# psoc6a2m register map
Vendor: Cypress Semiconductor; Series: psoc6a2m; File version: 1.0
CPU: CM4 r0p1, little endian, MPU, FPU, VTOR, 3 interrupt priority bits
Registers are 32-bit, read-write, reset 0x0 unless marked. A register's access mark holds for its fields unless they carry their own. Offsets are from the block's base; [hi:lo] are bit positions; lines under a group give offsets from that group; {n}, {i} and the like mark numbered series; 'fields as' and 'values as' point back to an identical list; <NAME> marks a mode.

## FLASHC — Flash controller
Base 0x40240000
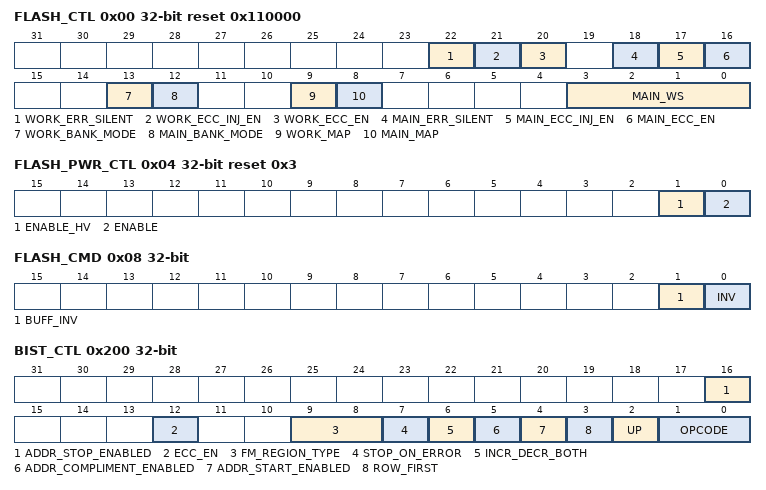
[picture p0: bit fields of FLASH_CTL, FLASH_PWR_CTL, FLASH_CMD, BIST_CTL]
0x00 FLASH_CTL reset 0x110000 — Control
  [22] WORK_ERR_SILENT — Specifies bus transfer behavior for a non-recoverable error on the FLASH macro work interface (either a non-correctable ECC error, a FLASH macro work interface internal error, a FLASH macro work interface memory hole access): '0': Bus transfer has a bus error. '1': Bus transfer does NOT have a bus error; i.e. the error is 'silent' In either case, the erroneous FLASH macro data is returned by the bus master interface. The erroneous data is NOT placed in a bus master interface's cache and/or buffer. This field is ONLY used by CPU bus transfers. Non-CPU bus transfers always have a bus transfer with a bus error, in case of a non-recoverable error. Note: All CPU bus masters have dedicated status registers (CM0_STATUS and CM4_STATUS) to register the occurence of FLASH macro work interface internal errors (non-correctable ECC errors and memory hole errors are NOT registered). Note: fault reporting can be used to identify the error that occured: - FLASH macro work interface internal error. - FLASH macro work interface non-recoverable ECC error. - FLASH macro work interface recoverable ECC error. - FLASH macro work interface memory hole error.
  [21] WORK_ECC_INJ_EN — Enable error injection for FLASH work interface. When '1', the parity (ECC_CTL.PARITY[6:0]) is used for a load from the ECC_CTL.WORD_ADDR[23:0] word address.
  [20] WORK_ECC_EN — Enable ECC checking for FLASH work interface: '0': Disabled. ECC checking/reporting on FLASH work interface is disabled. No correctable or non-correctable faults are reported. '1': Enabled.
  [18] MAIN_ERR_SILENT — Specifies bus transfer behavior for a non-recoverable error on the FLASH macro main interface (either a non-correctable ECC error, a FLASH macro main interface internal error, a FLASH macro main interface memory hole access): '0': Bus transfer has a bus error. '1': Bus transfer does NOT have a bus error; i.e. the error is 'silent' In either case, the erroneous FLASH macro data is returned by the bus master interface. The erroneous data is NOT placed in a bus master interface's cache and/or buffer. This field is ONLY used by CPU bus transfers. Non-CPU bus transfers always have a bus transfer with a bus error, in case of a non-recoverable error. Note: All CPU bus masters have dedicated status registers (CM0_STATUS and CM4_STATUS) to register the occurence of FLASH macro main interface internal errors (non-correctable ECC errors and memory hole errors are NOT registered). Note: fault reporting can be used to identify the error that occured: - FLASH macro main interface internal error. - FLASH macro main interface non-recoverable ECC error. - FLASH macro main interface recoverable ECC error. - FLASH macro main interface memory hole error.
  [17] MAIN_ECC_INJ_EN — Enable error injection for FLASH main interface. When '1', the parity (ECC_CTL.PARITY[7:0]) is used for a load from the ECC_CTL.WORD_ADDR[23:0] word address.
  [16] MAIN_ECC_EN — Enable ECC checking for FLASH main interface: '0': Disabled. ECC checking/reporting on FLASH main interface is disabled. No correctable or non-correctable faults are reported. '1': Enabled.
  [13] WORK_BANK_MODE — Specifies bank mode of FLASH macro work array. '0': Single bank mode. '1': Dual bank mode.
  [12] MAIN_BANK_MODE — Specifies bank mode of FLASH macro main array. '0': Single bank mode. '1': Dual bank mode.
  [9] WORK_MAP — Specifies mapping of FLASH macro work array. '0': Mapping A. '1': Mapping B. This field is only used when WORK_BANK_MODE is '1' (dual bank mode).
  [8] MAIN_MAP — Specifies mapping of FLASH macro main array. '0': Mapping A. '1': Mapping B. This field is only used when MAIN_BANK_MODE is '1' (dual bank mode).
  [3:0] MAIN_WS — FLASH macro main interface wait states: '0': 0 wait states. ... '15': 15 wait states
0x04 FLASH_PWR_CTL reset 0x3 — Flash power control
  [1] ENABLE_HV — Controls 'enable_hv' pin of the Flash memory.
  [0] ENABLE — Controls 'enable' pin of the Flash memory.
0x08 FLASH_CMD — Command
  [1] BUFF_INV — Invalidation of ALL buffers (does not invalidate the caches). SW writes a '1' to clear the buffers. HW sets this field to '0' when the operation is completed. The operation takes a maximum of three clock cycles on the slowest of the clk_slow and clk_fast clocks. Note: the caches only capture FLASH macro main array data. Therefore, invalidating just the buffers (BUFF_INV) does not invalidate captures main array data in the caches.
  [0] INV — Invalidation of ALL caches (for CM0+ and CM4) and ALL buffers. SW writes a '1' to clear the caches. HW sets this field to '0' when the operation is completed. The operation takes a maximum of three clock cycles on the slowest of the clk_slow and clk_fast clocks. The caches' LRU structures are also reset to their default state.
0x200 BIST_CTL — BIST control
  [16] ADDR_STOP_ENABLED — Specifies Flash BIST stop addresses: '0': Row and column addresses stop with their maximum/minimum values. '1': Row and column addresses stop with their values as specified by BIST_ADDR_STOP. This feature is supported only for simple increment/decrement patterns. It is not supported with address compliment pattern (BIST_CTL.ADDR_COMPLIMENT_ENABLED) or address pattern which increments/decrements both row address and column address (BIST_CTL.INCR_DECR_BOTH) for every read.
  [12] ECC_EN — Enable to test ECC data from Flash 0: ECC data output from Flash is not included for BIST test 1: ECC data output from Flash is included for BIST test
  [9:8] FM_REGION_TYPE — Specifies the Flash macro region to be tested. For eCT Flash 2'b00: Small sector region (SMS). 2'b01: Large sector region. 2'b1x: OTP region. This option is valid only when running BIST for eCT MAIN interface. Ignored when running BIST on WORK interface. For SONOS Flash 2'b00: Main flash region 2'b01: EEPROM region 2'b1x: SFLASH region
  [7] STOP_ON_ERROR — Specifies the BIST to continue indefinitely, regardless of occurrence of errors or not. '0': BIST controller doesn't stop on the data failures, it continues regardless of the errors. '1': BIST controller stops on when the first data failure is encounted.
  [6] INCR_DECR_BOTH — Specifies to generate patterns where both column address and row address are incremented/decremented simultaneously. '0': Generate normal increment/decrement patterns. '1': Generate address patterns with both row and column address changing. Example: With UP = 1 and ROW_FIRST = 0 00_00 01_01 10_10 11_11 00_01 01_10 10_11 11_00 00_10 ...
  [5] ADDR_COMPLIMENT_ENABLED — Specifies to generate address compliment patterns. '0': Generate normal increment/decrement patterns. '1': Generate address patterns which interleaves compliment of previous address in between. Example: The following is an exaple pattern, With UP=1 and ROW_FIRST =0 00_00 11_11 00_01 11_10 00_10 11_01 ...
  [4] ADDR_START_ENABLED — Specifies Flash BIST start addresses: '0': Row and column addresses start with their maximum/minimum values. '1': Row and column addresses start with their values as specified by BIST_ADDR_START. This feature is supported only for simple increment/decrement patterns. It is not supported with address compliment pattern (BIST_CTL.ADDR_COMPLIMENT_ENABLED) or address pattern which increments/decrements both row address and column address (BIST_CTL.INCR_DECR_BOTH) for every read.
  [3] ROW_FIRST — Specifies how the Flash BIST addresses are generated: '0': Column address is incremented/decremented till it reaches its maximum/minimum value. Once it reach its maximum/minimum value, it is set to its mimimum/maximum value and only then is the row address incremented/decremented. '1': Row address is incremented/decremented till it reaches its maximum/minimum value. Once it reach its maximum/minimum value, it is set to its mimimum/maximum value and only then is the column address incremented/decremented.
  [2] UP — Specifies direction in which Flash BIST steps through addresses: ''0': BIST steps through the Flash from the maximum row and column addresses (as specified by a design time configurtion parameter when ADDR_START_ENABLED is '0' and as specified by BIST_ADDR_START when ADDR_START_ENABLED is '1') to the minimum row and column addresses. '1': BIST steps through the Flash from the minimum row and column addresses ('0' when ADDR_START_ENABLED is '0' and as specified by BIST_ADDR_START when ADDR_START_ENABLED is '1') to the maximum row and column addresses.
  [1:0] OPCODE — This field specifies how the data check should be performed after reading the data from Flash memory. '0': Read the Flash and compare the output to BIST_DATA (R0). '1': Read the Flash and compare the output to the binary complement of BIST_DATA (R1). '2': Read the Flash and compare with BIST_DATA[] and compliment of BIST_DATA alternately (R01). The expected data of the first read is BIST_DATA, expected data of the second read is binary compliment of BIST_DATA, third read expected data is BIST_DATA, fourth read expected data is binary compliment of BIST_DATA and so on. '3': Similar to '2', but enables checker board pattern (where as OPCODE = 2 gives column stripe pattern). Note: OPCODE = 2 or 3 doesn;t support INCR_DECR_BOTH = 1 and ADDR_COMPLIMENT_ENABLED = 1.
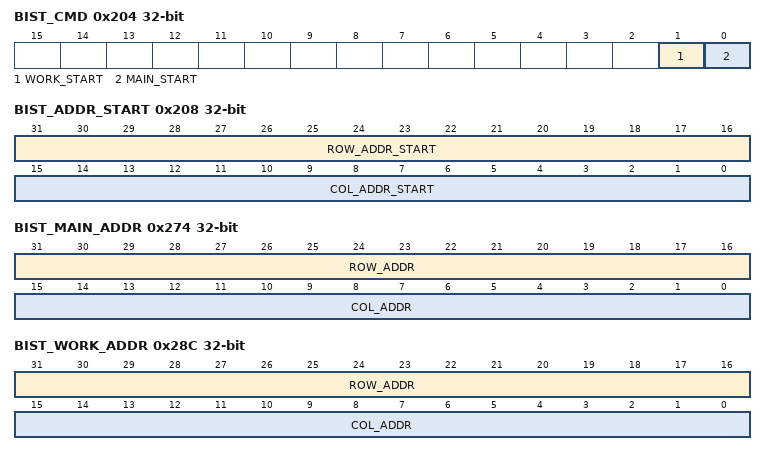
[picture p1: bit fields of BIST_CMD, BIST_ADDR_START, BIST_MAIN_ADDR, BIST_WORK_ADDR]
0x204 BIST_CMD — BIST command
  [1] WORK_START — 1': Start FLASH WORK BIST. Hardware set this field to '0' when BIST is completed.
  [0] MAIN_START — 1': Start FLASH MAIN BIST. Hardware set this field to '0' when BIST is completed.
0x208 BIST_ADDR_START — BIST address start register
  [31:16] ROW_ADDR_START — Row start address. Useful to apply BIST to a part of an Flash. The value of this field should be in a legal range (a value outside of the legal range has an undefined result, and may lock up the BIST state machine). This legal range is dependent on the number of rows of the SRAM the BIST is applied to (as specified by BIST_CTL.SRAMS_ENABLED). E.g. for a Flash with m columns, the legal range is [0, m-1].
  [15:0] COL_ADDR_START — Column start address. Useful to apply BIST to a part of an Flash. The value of this field should be in a legal range (a value outside of the legal range has an undefined result, and may lock up the BIST state machine). This legal range is dependent on the number of columns of the SRAM the BIST is applied to (as specified by BIST_CTL.SRAMS_ENABLED). E.g. for a Flash with n columns, the legal range is [0, n-1].
{0x20C+4i} BIST_DATA[{i}] (i=0..7) — BIST data register(s)
  [31:0] DATA — BIST data register to store the expected value for data comparison. For a 128-bit Flash memory, there will be 4 BIST_DATA registers to store 128-bit value.
{0x22C+4i} BIST_MAIN_DATA_ACT[{i}] (i=0..7) ro reset not defined — BIST (main) data actual register(s)
  [31:0] DATA — This field specified the actual Flash data output that caused the BIST failure.
{0x24C+4i} BIST_MAIN_DATA_EXP[{i}] (i=0..7) ro reset not defined — BIST (main) data expected register(s)
  [31:0] DATA — This field specified the expected Flash data output.
0x26C BIST_MAIN_DATA_ECC_ACT ro reset not defined — BIST (main) ECC data actual register
  [31:0] DATA — This field specified the actual Flash ECC data output.
0x270 BIST_MAIN_DATA_ECC_EXP ro reset not defined — BIST (main) ECC data expected register
  [31:0] DATA — This field specified the expected Flash ECC data output.
0x274 BIST_MAIN_ADDR ro reset not defined — BIST (main) address register
  [31:16] ROW_ADDR — Current row address.
  [15:0] COL_ADDR — Current column address.
0x278 BIST_MAIN_STATUS
  [0] FAIL — 0': BIST passed. '1': BIST failed.
0x27C BIST_WORK_DATA_ACT ro reset not defined — BIST (work) data actual register
  [31:0] DATA — This field specified the actual work Flash data output that caused the BIST failure.
0x280 BIST_WORK_DATA_EXP ro reset not defined — BIST (work) data expected register
  [31:0] DATA — This field specified the expected work Flash data output.
0x284 BIST_WORK_DATA_ECC_ACT ro reset not defined — BIST (work) ECC data actual register
  [6:0] DATA_ECC — This field specified the actual work Flash ECC data output.
0x288 BIST_WORK_DATA_ECC_EXP ro reset not defined — BIST (work) ECC data expected register
  [6:0] DATA_ECC — This field specified the expected work Flash ECC data output.
0x28C BIST_WORK_ADDR ro reset not defined — BIST (work) address register
  [31:16] ROW_ADDR — Current row address (work).
  [15:0] COL_ADDR — Current column address (work).
0x290 BIST_WORK_STATUS
  [0] FAIL — 0': BIST (work) passed. '1': BIST (work) failed.
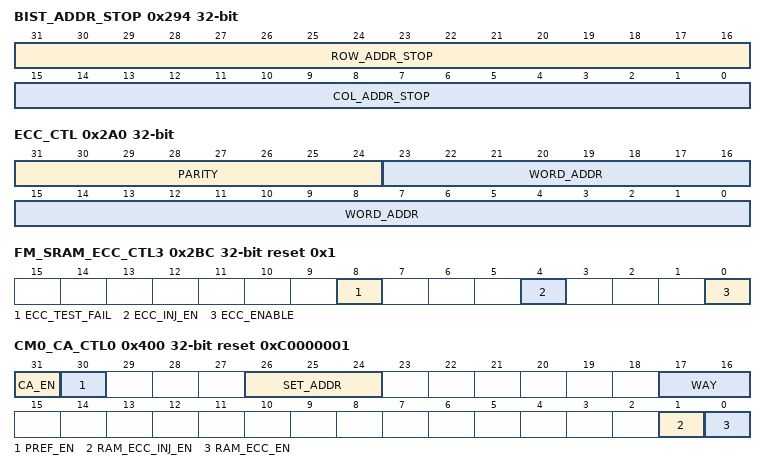
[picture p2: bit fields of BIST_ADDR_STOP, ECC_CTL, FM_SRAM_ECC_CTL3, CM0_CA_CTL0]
0x294 BIST_ADDR_STOP — BIST address stop register
  [31:16] ROW_ADDR_STOP — Row stop address. Useful to apply BIST to a part of an Flash. The value of this field should be in a legal range (a value outside of the legal range has an undefined result, and may lock up the BIST state machine). This legal range is dependent on the number of rows of the Flash the BIST is applied to. E.g. for a Flash with m columns, the legal range is [0, m-1].
  [15:0] COL_ADDR_STOP — Column stop address. Useful to apply BIST to a part of an Flash. The value of this field should be in a legal range (a value outside of the legal range has an undefined result, and may lock up the BIST state machine). This legal range is dependent on the number of columns of the Flash the BIST is applied to. E.g. for a Flash with n columns, the legal range is [0, n-1].
0x2A0 ECC_CTL — ECC control
  [31:24] PARITY — ECC parity to use for ECC error injection at address WORD_ADDR. - For cache SRAM ECC, the 7-bit parity PARITY[6:0] is for a 32-bit word. - For FLASH main interface ECC, the 8-bit parity PARITY[7:0] is for a 64-bit word. - For FLASH work interface ECC, the 7-bit parity PARITY[6:0] is for a 32-bit word.
  [23:0] WORD_ADDR — Specifies the word address where an error will be injected. - For cache SRAM ECC, the word address WORD_ADDR[23:0] is device address A[25:2]. On a FLASH macro refill to this word address and when the corresponding CM0/4_CA_CTL.RAM_ECC_INJ_EN bit is '1', the parity (PARITY[6:0]) is injected and stored in the cache. - For FLASH main interface ECC, the word address WORD_ADDR[23:0] is device address A[26:3]. On a FLASH main interface read and when FLASH_CTL.MAIN_ECC_INJ_EN bit is '1', the parity (PARITY[7:0]) replaces the FLASH macro parity (FLASH main interface read path is manipulated). - For FLASH work interface ECC, the word address WORD_ADDR[23:0] is device address A[24:2]. On a FLASH work interface read and when FLASH_CTL.WORK_ECC_INJ_EN bit is '1', the parity (PARITY[6:0]) replaces the FLASH macro parity (FLASH work interface read path is manipulated).
0x2B0 FM_SRAM_ECC_CTL0 — eCT Flash SRAM ECC control 0
  [31:0] ECC_INJ_DATA — 32-bit data for ECC error injection test of eCT Flash SRAM ECC logic.
0x2B4 FM_SRAM_ECC_CTL1 — eCT Flash SRAM ECC control 1
  [6:0] ECC_INJ_PARITY — 7-bit parity for ECC error injection test of eCT Flash SRAM ECC logic.
0x2B8 FM_SRAM_ECC_CTL2 ro — eCT Flash SRAM ECC control 2
  [31:0] CORRECTED_DATA — 32-bit corrected data output of the ECC syndrome logic.
0x2BC FM_SRAM_ECC_CTL3 reset 0x1 — eCT Flash SRAM ECC control 3
  [8] ECC_TEST_FAIL ro — Status of ECC test. 1 : ECC test failed because eCT Flash macro is busy and using the SRAM. 0: ECC was performed.
  [4] ECC_INJ_EN — eCT Flash SRAM ECC error injection test enable. Follow the steps below for ECC logic test: 1. Write corrupted or uncorrupted 39-bit data to FM_SRAM_ECC_CTL0/1 registers. 2. Set the ECC_INJ_EN bit to '1'. 3. Confirm that the bit ECC_TEST_FAIL is '0'. If this is not the case, start over at item 1 because the eCT Flash was not idle. 4. Check the corrected data in FM_SRAM_ECC_CTL2. 5. Confirm that fault was reported to fault structure, and check syndrome (only applicable if corrupted data was written in step 1). 6. If not finished, start over at 1 with different data.
  [0] ECC_ENABLE — ECC generation/check enable for eCT Flash SRAM memory.
0x400 CM0_CA_CTL0 reset 0xC0000001 — CM0+ cache control
  [31] CA_EN — Cache enable: '0': Disabled. The cache tag valid bits are reset to '0's and the cache LRU information is set to '1's (making way 0 the LRU way and way 3 the MRU way). '1': Enabled.
  [30] PREF_EN — Prefetch enable: '0': Disabled. '1': Enabled. Prefetching requires the cache to be enabled; i.e. ENABLED is '1'.
  [26:24] SET_ADDR — Specifies the cache set for which cache information is provided in CM0_CA_STATUS0/1/2.
  [17:16] WAY — Specifies the cache way for which cache information is provided in CM0_CA_STATUS0/1/2.
  [1] RAM_ECC_INJ_EN — Enable error injection for cache. When '1', the parity (ECC_CTL.PARITY[6:0]) is used when a refill is done from the FLASH macro to the ECC_CTL.WORD_ADDR[23:0] word address.
  [0] RAM_ECC_EN — Enable ECC checking for cache accesses: '0': Disabled. '1': Enabled.
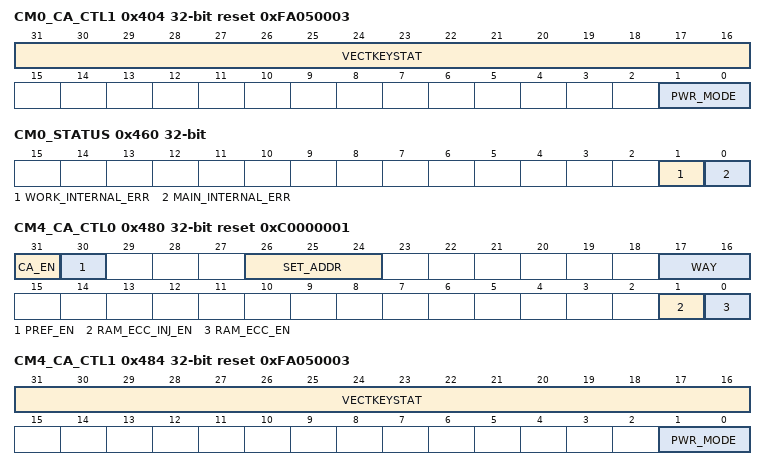
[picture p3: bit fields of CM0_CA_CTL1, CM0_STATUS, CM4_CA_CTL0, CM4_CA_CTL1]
0x404 CM0_CA_CTL1 reset 0xFA050003 — CM0+ cache control
  [31:16] VECTKEYSTAT ro — Register key (to prevent accidental writes). - Should be written with a 0x05fa key value for the write to take effect. - Always reads as 0xfa05.
  [1:0] PWR_MODE — Specifies power mode for CM0 cache.
    0=OFF (See CM4_PWR_CTL); 1=RSVD (Undefined); 2=RETAINED (See CM4_PWR_CTL); 3=ENABLED (See CM4_PWR_CTL)
0x408 CM0_CA_CTL2 reset 0x12C — CM0+ cache control
  [9:0] PWRUP_DELAY — Number clock cycles delay needed after power domain power up
0x440 CM0_CA_STATUS0 ro — CM0+ cache status 0
  [31:0] VALID32 — Sixteen valid bits of the cache line specified by CM0_CA_CTL.WAY and CM0_CA_CTL.SET_ADDR.
0x444 CM0_CA_STATUS1 ro reset not defined — CM0+ cache status 1
  [31:0] TAG — Cache line address of the cache line specified by CM0_CA_CTL.WAY and CM0_CA_CTL.SET_ADDR.
0x448 CM0_CA_STATUS2 ro reset not defined — CM0+ cache status 2
  [5:0] LRU — Six bit LRU representation of the cache set specified by CM0_CA_CTL.SET_ADDR. The encoding of the field is as follows ('X_LRU_Y' indicates that way X is Less Recently Used than way Y): Bit 5: 0_LRU_1: way 0 less recently used than way 1. Bit 4: 0_LRU_2. Bit 3: 0_LRU_3. Bit 2: 1_LRU_2. Bit 1: 1_LRU_3. Bit 0: 2_LRU_3.
0x460 CM0_STATUS — CM0+ interface status
  [1] WORK_INTERNAL_ERR — See CM0_STATUS.MAIN_INTERNAL_ERROR.
  [0] MAIN_INTERNAL_ERR — Specifies/registers the occurence of a FLASH macro main interface internal error (typically the result of a read access while a program erase opertion is ongoing) as a result of a CM0+ access. SW clears this field to '0'. HW sets this field to '1' on a FLASH macro main interface internal error. Typically, SW reads this field after a code section to detect the occurence of an error. Note: this field is independent of FLASH_CTL.MAIN_ERR_SILENT.
0x480 CM4_CA_CTL0 reset 0xC0000001 — CM4 cache control
  [31] CA_EN — See CM0_CA_CTL.
  [30] PREF_EN — See CM0_CA_CTL.
  [26:24] SET_ADDR — See CM0_CA_CTL.
  [17:16] WAY — See CM0_CA_CTL.
  [1] RAM_ECC_INJ_EN — See CM0_CA_CTL.
  [0] RAM_ECC_EN — See CM0_CA_CTL.
0x484 CM4_CA_CTL1 reset 0xFA050003 — CM4 cache control
  [31:16] VECTKEYSTAT ro — Register key (to prevent accidental writes). - Should be written with a 0x05fa key value for the write to take effect. - Always reads as 0xfa05.
  [1:0] PWR_MODE — Specifies power mode for CM4 cache.
    values as CM0_CA_CTL1.PWR_MODE
0x488 CM4_CA_CTL2 reset 0x12C — CM4 cache control
  fields as CM0_CA_CTL2
0x4C0 CM4_CA_STATUS0 ro — CM4 cache status 0
  [31:0] VALID32 — See CM0_CA_STATUS0.
0x4C4 CM4_CA_STATUS1 ro reset not defined — CM4 cache status 1
  [31:0] TAG — See CM0_CA_STATUS1.
0x4C8 CM4_CA_STATUS2 ro reset not defined — CM4 cache status 2
  [5:0] LRU — See CM0_CA_STATUS2.
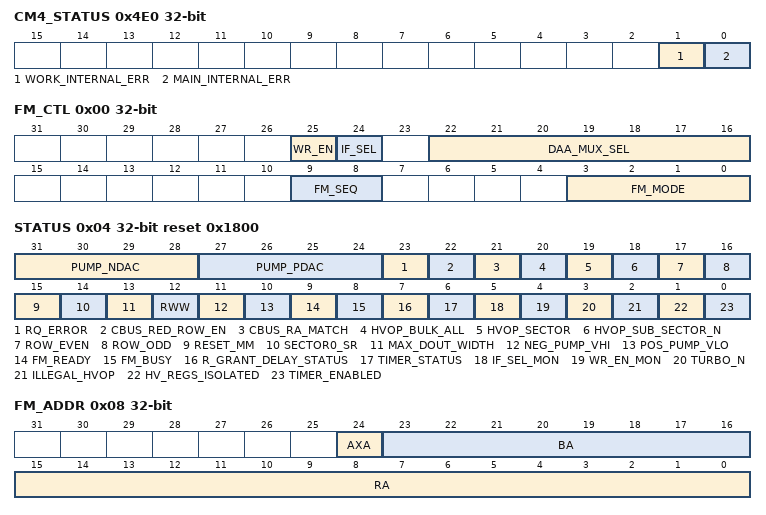
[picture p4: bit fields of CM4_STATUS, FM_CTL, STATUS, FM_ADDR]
0x4E0 CM4_STATUS — CM4 interface status
  [1] WORK_INTERNAL_ERR — See CM0_STATUS.MAIN_INTERNAL_ERROR.
  [0] MAIN_INTERNAL_ERR — See CM0_STATUS.MAIN_INTERNAL_ERROR.
0x500 CRYPTO_BUFF_CTL reset 0x40000000 — Cryptography buffer control
  [30] PREF_EN — Prefetch enable: '0': Disabled. '1': Enabled. A prefecth will be done when there is read 'hit' on the last 32-bit word of the buffer. For eCT work Flash, prefetch will not be done.
0x580 DW0_BUFF_CTL reset 0x40000000 — Datawire 0 buffer control
  [30] PREF_EN — See CRYPTO_BUFF_CTL.
0x600 DW1_BUFF_CTL reset 0x40000000 — Datawire 1 buffer control
  [30] PREF_EN — See CRYPTO_BUFF_CTL.
0x680 DMAC_BUFF_CTL reset 0x40000000 — DMA controller buffer control
  [30] PREF_EN — See CRYPTO_BUFF_CTL.
0x700 EXT_MS0_BUFF_CTL reset 0x40000000 — External master 0 buffer control
  [30] PREF_EN — See CRYPTO_BUFF_CTL.
0x780 EXT_MS1_BUFF_CTL reset 0x40000000 — External master 1 buffer control
  [30] PREF_EN — See CRYPTO_BUFF_CTL.
0xF000 FM_CTL group — Flash Macro Registers
  0x00 FM_CTL — Flash macro control
    [25] WR_EN — '0': normal mode '1': Fm Write Enable Note: IF_SEL and WR_EN cannot be changed at the same time
    [24] IF_SEL — Interface selection. Specifies the interface that is used for flash memory read operations: '0': R interface is used (default value). In this case, the flash memory address is provided as part of the R signal interface. '1': C interface is used. In this case, the flash memory address is provided by FM_MEM_ADDR (the page address) and by the C interface access offset in the FM_MEM_DATA structure. Note: IF_SEL and WR_EN cannot be changed at the same time
    [22:16] DAA_MUX_SEL — Direct memory cell access address.
    [9:8] FM_SEQ — Requires (IF_SEL|WR_EN)=1 Flash macro sequence selection
    [3:0] FM_MODE — Requires (IF_SEL|WR_EN)=1 Flash macro mode selection
  0x04 STATUS ro reset 0x1800
    [31:28] PUMP_NDAC — Test_only, internal node: regif ndac outputs to pos pump
    [27:24] PUMP_PDAC — Test_only, internal node: regif pdac outputs to pos pump
    [23] RQ_ERROR — Test_only, internal node: rq_error sync-de in clk_c domain
    [22] CBUS_RED_ROW_EN — Test_only, internal node: mpcon red_row_en
    [21] CBUS_RA_MATCH — Test_only, internal node: mpcon ra match
    [20] HVOP_BULK_ALL — Test_only, internal node: mpcon bk_all
    [19] HVOP_SECTOR — Test_only, internal node: mpcon bk_sec
    [18] HVOP_SUB_SECTOR_N — Test_only, internal node: mpcon bk_subb
    [17] ROW_EVEN — Test_only, internal node: mpcon row_even
    [16] ROW_ODD — Test_only, internal node: mpcon row_odd
    [15] RESET_MM — Test_only, internal node: mpcon reset_mm
    [14] SECTOR0_SR — 0' - Sector 0 does not contain special rows. The special rows are located in separate special sectors. '1' - Sector 0 contains special rows
    [13] MAX_DOUT_WIDTH — Internal memory core max data out size (number of data out bits per colunm): '0' - x128 bits '1' - x256 bits
    [12] RWW — FM Type (Read While Write or Not Read While Write): '0' - Non RWW FM Type '1' - RWW FM Type
    [11] NEG_PUMP_VHI
    [10] POS_PUMP_VLO
    [9] FM_READY — 0': FM not ready '1': FM ready
    [8] FM_BUSY — 0': FM not busy '1': FM BUSY : R_GRANT is 0 as result of a busy request from FM ready, or from HV operations.
    [7] R_GRANT_DELAY_STATUS — 0': R_GRANT_DELAY timer is not running '1': R_GRANT_DELAY timer is running
    [6] TIMER_STATUS — The actual timer state sync-ed in clk_c domain: '0': timer is not running: '1:': timer is running;
    [5] IF_SEL_MON — FM_CTL.IF_SEL bit after being synchronized in clk_r domain
    [4] WR_EN_MON — FM_CTL.WR_EN bit after being synchronized in clk_r domain
    [3] TURBO_N — After FM power up indicates the analog blocks currents are boosted to faster reach their functional state.. Used in the testchip boot only as an 'FM READY' flag. '0' - turbo mode '1' - normal mode
    [2] ILLEGAL_HVOP — Indicates a bulk,sector erase, program has been requested when axa=1 '0' - no error '1' - illegal HV operation error
    [1] HV_REGS_ISOLATED — Indicates the isolation status at HV trim and redundancy registers inputs '0' - Not isolated, writing permitted '1' - isolated writing disabled
    [0] TIMER_ENABLED — This is the timer_en bit set by writing a '1' in the TIMER_CTL bit 31. It is reset by HW when the timer expires '0': timer not running '1': Timer is enabled and not expired yet
  0x08 FM_ADDR — Flash macro address
    [24] AXA — Auxiliairy address field: '0': regular flash memory. '1': supervisory flash memory.
    [23:16] BA — Bank address.
    [15:0] RA — Row address.
  0x0C BOOKMARK — Bookmark register - keeps the current FW HV seq
    [31:0] BOOKMARK — Used by FW. Keeps the Current HV cycle sequence
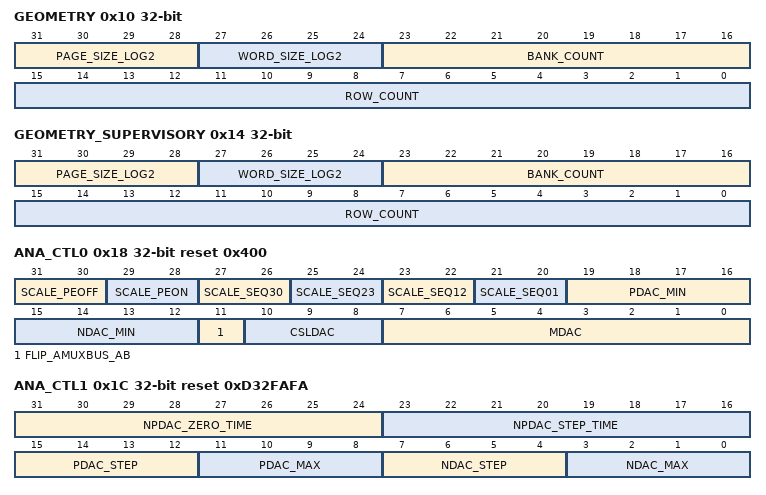
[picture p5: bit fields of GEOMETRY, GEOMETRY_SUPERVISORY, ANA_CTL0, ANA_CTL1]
  0x10 GEOMETRY ro — Regular flash geometry
    [31:28] PAGE_SIZE_LOG2 — Number of Bytes per page (log 2): '0': 1 Byte '1': 2 Bytes '2': 4 Bytes ... '15': 32768 Bytes The currently planned flash macros have a page size of either 256 Byte or 512 Byte, resulting in PAGE_SIZE_LOG2 settings of 8 and 9 respectively.
    [27:24] WORD_SIZE_LOG2 — Number of Bytes per word (log 2). A word is defined as the data that is read from the flash macro over the R interface with a single read access: '0': 1 Byte '1': 2 Bytes '2': 4 Bytes ... '7': 128 Bytes The currently planned flash macros have a word size of either 32-bit, 64-bit or 128-bit, resulting in WORD_SIZE_LOG2 settings of 2, 3 and 4 respectively.
    [23:16] BANK_COUNT — Number of banks (minus 1): '0': 1 bank '1': 2 banks ... '255': 256 banks
    [15:0] ROW_COUNT — Number of rows (minus 1): '0': 1 row '1': 2 rows '2': 3 rows ... '65535': 65536 rows
  0x14 GEOMETRY_SUPERVISORY ro — Supervisory flash geometry
    [31:28] PAGE_SIZE_LOG2 — Number of Bytes per page (log 2). See GEOMETRY.PAGE_SIZE_LOG2. Typically, PAGE_SIZE_LOG2 equals GEOMETRY.PAGE_SIZE_LOG2.
    [27:24] WORD_SIZE_LOG2 — Number of Bytes per word (log 2). See GEOMETRY.WORD_SIZE_LOG2. Typically, WORD_SIZE_LOG2 equals GEOMETRY.WORD_SIZE_LOG2.
    [23:16] BANK_COUNT — Number of banks (minus 1). BANK_COUNT is less or equal to GEOMETRY.BANK_COUNT.
    [15:0] ROW_COUNT — Number of rows (minus 1). ROW_COUNT is typically less than GEOMETRY.ROW_COUNT
  0x18 ANA_CTL0 reset 0x400 — Analog control 0
    [31:30] SCALE_PEOFF — Scale for R_GRANT_DELAY on PE OFF transition: '00': 0.125uS '01': 1uS '10': 10uS '11': 100uS
    [29:28] SCALE_PEON — Scale for R_GRANT_DELAY on PE On transition: '00': 0.125uS '01': 1uS '10': 10uS '11': 100uS
    [27:26] SCALE_SEQ30 — Scale for R_GRANT_DELAY on seq3-seq0 transition: '00': 0.125uS '01': 1uS '10': 10uS '11': 100uS
    [25:24] SCALE_SEQ23 — Scale for R_GRANT_DELAY on seq2-seq3 transition: '00': 0.125uS '01': 1uS '10': 10uS '11': 100uS
    [23:22] SCALE_SEQ12 — Scale for R_GRANT_DELAY on seq1-seq2 transition: '00': 0.125uS '01': 1uS '10': 10uS '11': 100uS
    [21:20] SCALE_SEQ01 — Scale for R_GRANT_DELAY on seq0-seq1 transition: '00': 0.125uS '01': 1uS '10': 10uS '11': 100uS
    [19:16] PDAC_MIN — PDAC staircase min value
    [15:12] NDAC_MIN — NDAC staircase min value
    [11] FLIP_AMUXBUS_AB — Flips amuxbusa and amuxbusb '0': amuxbusa, amuxbusb '1': amuxbusb, amuxbusb
    [10:8] CSLDAC — Trimming of common source line DAC.
    [7:0] MDAC — Trimming of the output margin Voltage as a function of Vpos and Vneg.
  0x1C ANA_CTL1 reset 0xD32FAFA — Analog control 1
    [31:24] NPDAC_ZERO_TIME — Ndac/Pdac LO duration: (1uS .. 255uS) * 8 When 0, N/PDAC don't return to 0
    [23:16] NPDAC_STEP_TIME — Ndac/Pdac step duration: (1uS .. 255uS) * 8 When = 0 N/PDAC_MAX control the pumps
    [15:12] PDAC_STEP — Pdac step increment
    [11:8] PDAC_MAX — Pdac Max Value.Trimming of positive pump output Voltage:
    [7:4] NDAC_STEP — Ndac step increment
    [3:0] NDAC_MAX — Ndac Max Value.Trimming of negative pump output Voltage.
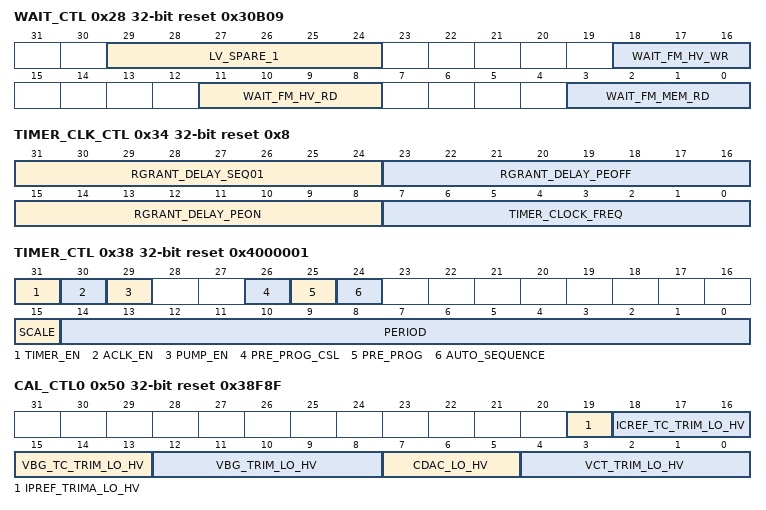
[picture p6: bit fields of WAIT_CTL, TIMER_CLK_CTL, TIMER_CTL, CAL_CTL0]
  0x28 WAIT_CTL reset 0x30B09 — Wait State control
    [29:24] LV_SPARE_1 — Spare register
    [18:16] WAIT_FM_HV_WR — Number of C interface wait cycles (on 'clk_c') for a write to the high Voltage page latches.
    [11:8] WAIT_FM_HV_RD — Number of C interface wait cycles (on 'clk_c') for a read from the high Voltage page latches. Common for reading HV Page Latches and the DATA_COMP_RESULT bit
    [3:0] WAIT_FM_MEM_RD — Number of C interface wait cycles (on 'clk_c') for a read from the memory
  0x34 TIMER_CLK_CTL reset 0x8 — Timer prescaler (clk_t to timer clock frequency divider)
    [31:24] RGRANT_DELAY_SEQ01 — R-grant blocking delay on seq0-seq1 transition. Scale = ANA_CTL0.SCALE_SEQ01 When = 0 R_GRANT_DELAY control is disabled when IF_SEL=1 R_GRANT_DELAY control is disabled
    [23:16] RGRANT_DELAY_PEOFF — R-grant blocking delay on PE OFF. Scale = ANA_CTL0.SCALE_PEOFF When = 0 R_GRANT_DELAY control is disabled when IF_SEL=1 R_GRANT_DELAY control is disabled
    [15:8] RGRANT_DELAY_PEON — R-grant blocking delay on PE ON. Scale = ANA_CTL0.SCALE_PEON When = 0 R_GRANT_DELAY control is disabled when IF_SEL=1 R_GRANT_DELAY control is disabled
    [7:0] TIMER_CLOCK_FREQ — Clk_t frequency divider to provide the 1MHz reference clock for the Regif Timer. Equal to the frequency in MHz of the timer clock 'clk_t'. Example: if 'clk_t' has a frequency of 4 MHz then this field value is '4' Max clk_t frequency = 100MHz. This field is updated at runtime with the 'SW_TIMER_CLOCK_FREQ ' value from the HV parameters table
  0x38 TIMER_CTL reset 0x4000001 — Timer control
    [31] TIMER_EN — Timer enable: '0': disabled '1': enabled. SW sets this field to '1' to start the timer. HW sets this field to '0' when the timer is expired.
    [30] ACLK_EN — ACLK enable (generates a single cycle pulse for the FM): '0': disabled '1': enabled. SW set this field to '1' to generate a single cycle pulse. HW sets this field to '0' when the pulse is generated.
    [29] PUMP_EN — Pump enable: '0': disabled '1': enabled (also requires FM_CTL.IF_SEL to be '1', this additional restriction is reuired to prevent non intential clearing of the FM). SW sets this field to '1' to generate a single PE pulse. HW clears this field when timer is expired.
    [26] PRE_PROG_CSL — 0' CSL lines driven by CSL_DAC '1' CSL lines driven by VNEG_G
    [25] PRE_PROG — '1' during pre-program operation
    [24] AUTO_SEQUENCE — 1': Starts1 the HV sutomatic sequencing Cleared by HW
    [15] SCALE — Timer tick scale: '0': 1 microsecond. '1': 100 microseconds.
    [14:0] PERIOD — Timer period in either microseconds (SCALE is '0') or 100's of microseconds (SCALE is '1') multiples.
  0x3C ACLK_CTL wo — MPCON clock
    [0] ACLK_GEN — A write to this register generates the clock pulse for HV control registers (mpcon outputs)
  0x40 INTR — Interrupt
    [0] TIMER_EXPIRED — Set to '1', when event is detected. Write INTR field with '1', to clear bit. Write INTR_SET field with '1', to set bit.
  0x44 INTR_SET — Interrupt set
    [0] TIMER_EXPIRED — Write INTR_SET field with '1' to set corresponding INTR field (a write of '0' has no effect).
  0x48 INTR_MASK — Interrupt mask
    [0] TIMER_EXPIRED — Mask for corresponding field in INTR register.
  0x4C INTR_MASKED ro — Interrupt masked
    [0] TIMER_EXPIRED — Logical and of corresponding request and mask fields.
  0x50 CAL_CTL0 reset 0x38F8F — Cal control BG LO trim bits
    [19] IPREF_TRIMA_LO_HV — Adds 100-150nA boost on IPREF_LO
    [18:16] ICREF_TC_TRIM_LO_HV — LO Bandgap Current Temperature Compensation trim control
    [15:13] VBG_TC_TRIM_LO_HV — LO Bandgap Voltage Temperature Compensation trim control
    [12:8] VBG_TRIM_LO_HV — LO Bandgap Voltage trim control.
    [7:5] CDAC_LO_HV — LO Temperature compensated trim DAC. To control Vcstat slope for Vpos.
    [4:0] VCT_TRIM_LO_HV — LO Bandgap Voltage Temperature Compensation trim control.
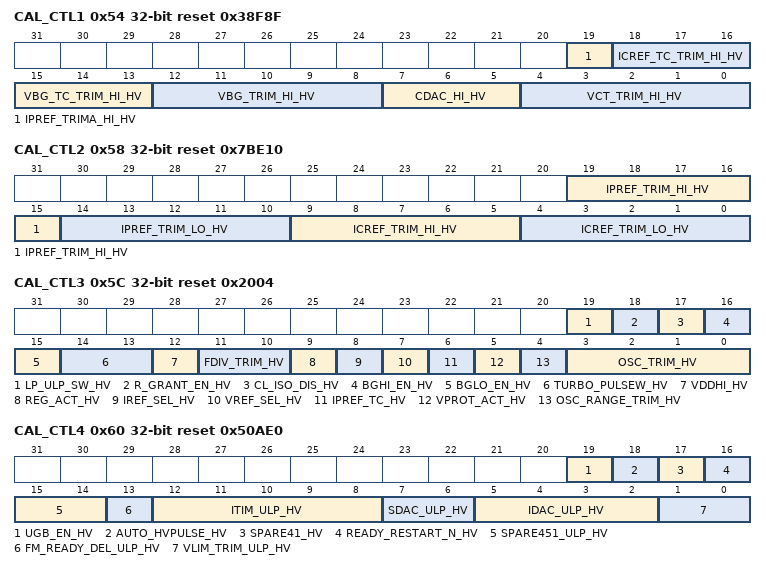
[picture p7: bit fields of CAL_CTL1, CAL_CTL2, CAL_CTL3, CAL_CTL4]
  0x54 CAL_CTL1 reset 0x38F8F — Cal control BG HI trim bits
    [19] IPREF_TRIMA_HI_HV — Adds 100-150nA boost on IPREF_HI
    [18:16] ICREF_TC_TRIM_HI_HV — HI Bandgap Current Temperature Compensation trim control.
    [15:13] VBG_TC_TRIM_HI_HV — HI Bandgap Voltage Temperature Compensation trim control.
    [12:8] VBG_TRIM_HI_HV — HI Bandgap Voltage trim control.
    [7:5] CDAC_HI_HV — HI Temperature compensated trim DAC. To control Vcstat slope for Vpos.
    [4:0] VCT_TRIM_HI_HV — HI Bandgap Voltage Temperature Compensation trim control.
  0x58 CAL_CTL2 reset 0x7BE10 — Cal control BG LO&HI trim bits
    [19:15] IPREF_TRIM_HI_HV — HI Bandgap IPTAT trim control.
    [14:10] IPREF_TRIM_LO_HV — LO Bandgap IPTAT trim control.
    [9:5] ICREF_TRIM_HI_HV — HI Bandgap Current trim control.
    [4:0] ICREF_TRIM_LO_HV — LO Bandgap Current trim control.
  0x5C CAL_CTL3 reset 0x2004 — Cal control osc trim bits, idac, sdac, itim
    [19] LP_ULP_SW_HV — LP<-->ULP switch for trim signals: '0': LP '1': ULP
    [18] R_GRANT_EN_HV — '0': r_grant handshake disabled, r_grant always 1. '1': r_grand handshake enabled
    [17] CL_ISO_DIS_HV — 0': The internal logic controlls the CL isolation '1': Forces CL bypass
    [16] BGHI_EN_HV — 0: Normal (Automatic change over from HI to LO) 1: Force enable HI Bandgap When both BGLO_EN_HV and BGHI_EN_HV are HIGH, only BGHI output is used and turbo_hv_n pulse is active
    [15] BGLO_EN_HV — 0: Normal (Automatic change over from HI to LO) 1: Force enable LO Bandgap
    [14:13] TURBO_PULSEW_HV — Turbo pulse width trim (Typical) 00: 40 us 01: 20 us 10: 15 us 11: 8 us
    [12] VDDHI_HV — '0': vdd < 2.3V '1': vdd >= 2.3V '0' setting can used for vdd > 2.3V also, but with a current penalty.
    [11:10] FDIV_TRIM_HV — FDIV_TRIM_HV[1:0]: Assuming oscillator frequency of 8MHz in standby. Following are the clock frequencies seen by doubler 2b00' F = 1MHz '2b01' F = 0.5MHz '2b10' F = 2MHz '2b11' F = 4MHz
    [9] REG_ACT_HV — 0: VBST regulator will operate in active/standby mode based on control signal. 1: Forces the VBST regulator in active mode all the time
    [8] IREF_SEL_HV — Current reference: '0': internal current reference '1': external current reference
    [7] VREF_SEL_HV — Voltage reference: '0': internal bandgap reference '1': external voltage reference
    [6] IPREF_TC_HV — 0: Increases the IPREF Tempco by subtracting ICREF from IPREF - IPREF internal will be 0.5uA 1: Reduces the IPREF Tempco without subtracting ICREF from IPREF - IPREF internal will be 1uA
    [5] VPROT_ACT_HV — Forces VPROT in active mode all the time
    [4] OSC_RANGE_TRIM_HV — 0: Oscillator High Frequency Range 1: Oscillator Low Frequency range
    [3:0] OSC_TRIM_HV — Flash macro pump clock trim control.
  0x60 CAL_CTL4 reset 0x50AE0 — Cal Control Vlim, SA, fdiv, reg_act
    [19] UGB_EN_HV — UGB enable in TM control
    [18] AUTO_HVPULSE_HV — 0: HV Pulse controlled by FW '1': HV Pulse controlled by Hardware
    [17] SPARE41_HV
    [16] READY_RESTART_N_HV — Toggle: 1-->0, wait 1us, 0-->1 to restart the Ready delay and create an R-grant blockage for 10uS
    [15:14] SPARE451_ULP_HV
    [13] FM_READY_DEL_ULP_HV — '0': Default '1': Delayed by 1us
    [12:8] ITIM_ULP_HV — Trimming of timing current
    [7:6] SDAC_ULP_HV — Sets the sense current reference temp slope. Refer to trim tables for details.
    [5:2] IDAC_ULP_HV — Sets the sense current reference offset value. Refer to trim tables for details.
    [1:0] VLIM_TRIM_ULP_HV — VLIM_TRIM[1:0]: '2b00' V2 = 650mV '2b01' V2 = 600mV '2b10' V2 = 750mV '2b11' V2 = 700mV
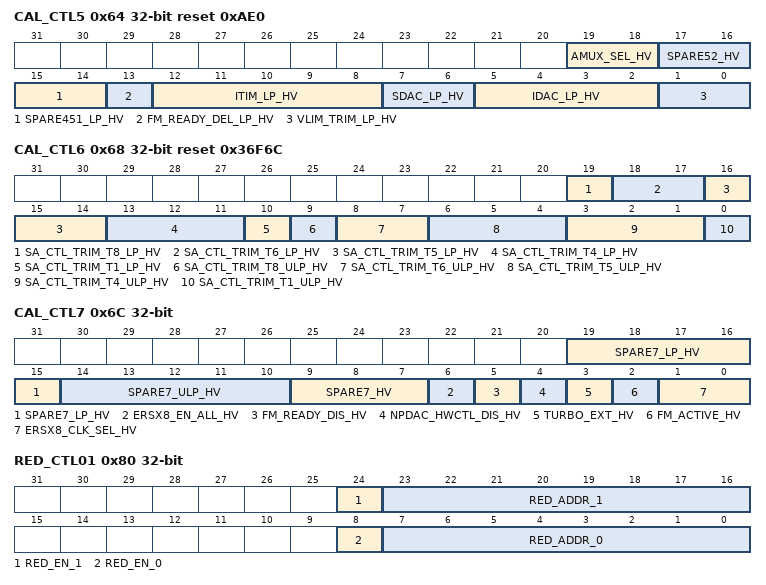
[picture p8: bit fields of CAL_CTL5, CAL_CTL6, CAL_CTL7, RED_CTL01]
  0x64 CAL_CTL5 reset 0xAE0 — Cal control
    [19:18] AMUX_SEL_HV — Amux Select in AMUX_UGB '00' : Bypass UGB for both amuxbusa and amuxbusb '01' : Bypass UGB for amuxbusb while passing amuxbusa through UGB. '10' : Bypass UGB for amuxbusa while passing amuxbusb through UGB. '11' : UGB Calibrate mode
    [17:16] SPARE52_HV
    [15:14] SPARE451_LP_HV
    [13] FM_READY_DEL_LP_HV — '0': Default '1': Delayed by 1us
    [12:8] ITIM_LP_HV — Trimming of timing current
    [7:6] SDAC_LP_HV — Sets the sense current reference temp slope. Refer to trim tables for details.
    [5:2] IDAC_LP_HV — Sets the sense current reference offset value. Refer to trim tables for details.
    [1:0] VLIM_TRIM_LP_HV — VLIM_TRIM[1:0]: '2b00' V2 = 650mV '2b01' V2 = 600mV '2b10' V2 = 750mV '2b11' V2 = 700mV
  0x68 CAL_CTL6 reset 0x36F6C — SA trim LP/ULP
    [19] SA_CTL_TRIM_T8_LP_HV — saen3 pulse width trim (Current trim)
    [18:17] SA_CTL_TRIM_T6_LP_HV — SA_CTL_TRIM_T6_LP_HV<1>= eni (enable current trim) SA_CTL_TRIM_T6_LP_HV<0> = ecn (enable cap trim)
    [16:14] SA_CTL_TRIM_T5_LP_HV — SA_CTL_TRIM_T5_LP_HV<2>= evi (integration current trim) SA_CTL_TRIM_T5_LP_HV<1:0> = evc (integration cap trim)
    [13:11] SA_CTL_TRIM_T4_LP_HV — SA_CTL_TRIM_T4_LP_HV<2>= eqi (eq current trim) SA_CTL_TRIM_T4_LP_HV<1:0> = eqc (eq cap trim)
    [10] SA_CTL_TRIM_T1_LP_HV — clk_trk delay
    [9] SA_CTL_TRIM_T8_ULP_HV — saen3 pulse width trim (Current trim)
    [8:7] SA_CTL_TRIM_T6_ULP_HV — SA_CTL_TRIM_T6_ULP_HV<1>= eni (enable current trim) SA_CTL_TRIM_T6_ULP_HV<0> = ecn (enable cap trim)
    [6:4] SA_CTL_TRIM_T5_ULP_HV — SA_CTL_TRIM_T5_ULP_HV<2>= evi (integration current trim) SA_CTL_TRIM_T5_ULP_HV<1:0> = evc (integration cap trim)
    [3:1] SA_CTL_TRIM_T4_ULP_HV — SA_CTL_TRIM_T4_ULP_HV<2>= eqi (eq current trim) SA_CTL_TRIM_T4_ULP_HV<1:0> = eqc (eq cap trim)
    [0] SA_CTL_TRIM_T1_ULP_HV — clk_trk delay
  0x6C CAL_CTL7 — Cal control
    [19:15] SPARE7_LP_HV
    [14:10] SPARE7_ULP_HV
    [9:7] SPARE7_HV
    [6] ERSX8_EN_ALL_HV — 0': Staggered turn on/off of GWL '1': GWL are turned on/off at the same time (old FM legacy)
    [5] FM_READY_DIS_HV — 0': fm ready is enabled '1': fm ready is disabled (fm_ready is always '1')
    [4] NPDAC_HWCTL_DIS_HV — 0': ndac, pdac staircase hardware controlled '1': ndac, pdac staircase disabled. Enables FW control.
    [3] TURBO_EXT_HV — 0: Normal operation 1: Uses external turbo pulse
    [2] FM_ACTIVE_HV — 0: Normal operation 1: Forces FM SYS in active mode
    [1:0] ERSX8_CLK_SEL_HV — Clock frequency into the ersx8 shift register block ''00': Oscillator clock ''01': Oscillator clock / 2 ''10': Oscillator clock / 4 ''11': Oscillator clock
  0x80 RED_CTL01 — Redundancy Control normal sectors 0,1
    [24] RED_EN_1 — '1': Redundancy Enable for Sector 1
    [23:16] RED_ADDR_1 — Bad Row Pair Address for Sector 1
    [8] RED_EN_0 — '1': Redundancy Enable for Sector 0
    [7:0] RED_ADDR_0 — Bad Row Pair Address for Sector 0
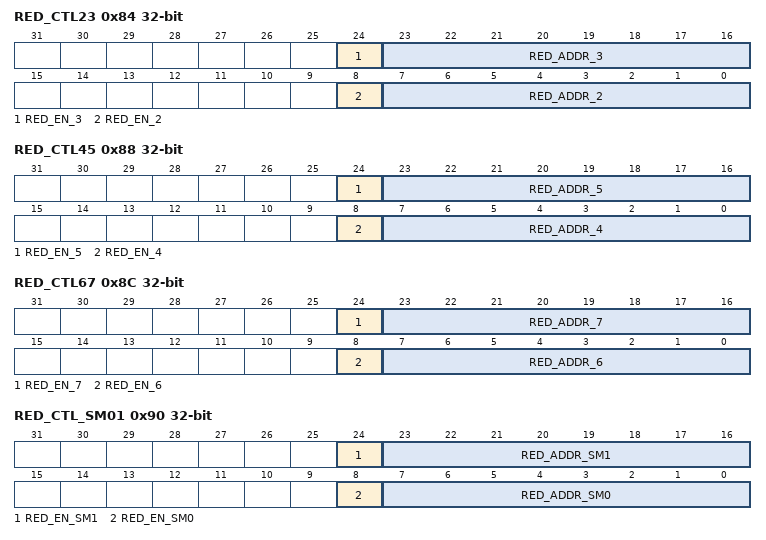
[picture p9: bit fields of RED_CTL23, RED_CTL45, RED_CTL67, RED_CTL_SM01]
  0x84 RED_CTL23 — Redundancy Control normal sectors 2,3
    [24] RED_EN_3 — 1': Redundancy Enable for Sector 3
    [23:16] RED_ADDR_3 — Bad Row Pair Address for Sector 3
    [8] RED_EN_2 — 1': Redundancy Enable for Sector 2
    [7:0] RED_ADDR_2 — Bad Row Pair Address for Sector 2
  0x88 RED_CTL45 — Redundancy Control normal sectors 4,5
    [24] RED_EN_5 — 1': Redundancy Enable for Sector 5
    [23:16] RED_ADDR_5 — Bad Row Pair Address for Sector 5
    [8] RED_EN_4 — 1': Redundancy Enable for Sector 4
    [7:0] RED_ADDR_4 — Bad Row Pair Address for Sector 4
  0x8C RED_CTL67 — Redundancy Control normal sectors 6,7
    [24] RED_EN_7 — 1': Redundancy Enable for Sector 7
    [23:16] RED_ADDR_7 — Bad Row Pair Address for Sector 7
    [8] RED_EN_6 — 1': Redundancy Enable for Sector 6
    [7:0] RED_ADDR_6 — Bad Row Pair Address for Sector 6
  0x90 RED_CTL_SM01 — Redundancy Control special sectors 0,1
    [24] RED_EN_SM1 — Redundancy Enable for Special Sector 1
    [23:16] RED_ADDR_SM1 — Bad Row Pair Address for Special Sector 1
    [8] RED_EN_SM0 — Redundancy Enable for Special Sector 0
    [7:0] RED_ADDR_SM0 — Bad Row Pair Address for Special Sector 0
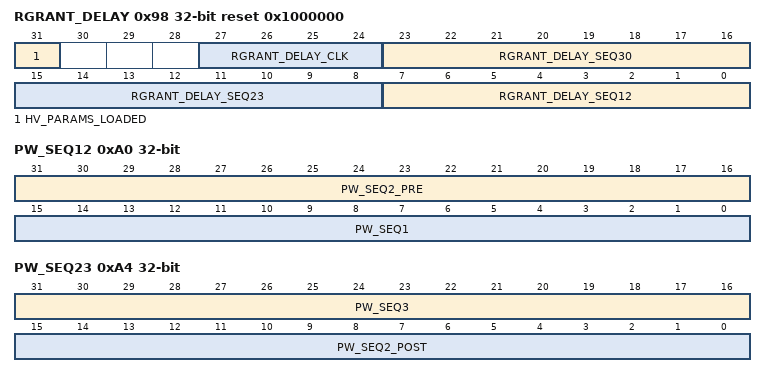
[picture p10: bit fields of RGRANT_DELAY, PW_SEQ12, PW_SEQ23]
  0x98 RGRANT_DELAY reset 0x1000000
    [31] HV_PARAMS_LOADED — 0': HV Pulse common params not loaded '1': HV Pulse common params loaded: r-grant delays, r-grant scale, prescaler, timer values for seq1,seq2_pre, seq2_post, seq3
    [27:24] RGRANT_DELAY_CLK — Frequency divider from clk_t to create the 8MHz reference clock for R_grant delay The value of this field is the integer result of 'clk_t frequency / 8'. Example: for clk_t=100 this field is INT(100/8) =12. This field is updated at runtime with the 'SW_RGRANT_DELAY_CLK ' value from the HV parameters table
    [23:16] RGRANT_DELAY_SEQ30 — R-grant blocking delay on seq3-seq0 transition. Scale = ANA_CTL0.SCALE_SEQ30 When = 0 R_GRANT_DELAY control is disabled when IF_SEL=1 R_GRANT_DELAY control is disabled
    [15:8] RGRANT_DELAY_SEQ23 — R-grant blocking delay on seq2-seq3 transition. Scale = ANA_CTL0.SCALE_SEQ23 When = 0 R_GRANT_DELAY control is disabled when IF_SEL=1 R_GRANT_DELAY control is disabled
    [7:0] RGRANT_DELAY_SEQ12 — R-grant blocking delay on seq1-seq2 transition. Scale = ANA_CTL0.SCALE_SEQ12 When = 0 R_GRANT_DELAY control is disabled when IF_SEL=1 R_GRANT_DELAY control is disabled
  0xA0 PW_SEQ12 — HV Pulse Delay for seq 1&2 pre
    [31:16] PW_SEQ2_PRE — Seq2 pre delay
    [15:0] PW_SEQ1 — Seq1 delay
  0xA4 PW_SEQ23 — HV Pulse Delay for seq2 post & seq3
    [31:16] PW_SEQ3 — Seq3 delay
    [15:0] PW_SEQ2_POST — Seq2 post delay
  0x7FC FM_PL_WRDATA_ALL — Flash macro write page latches all
    [31:0] DATA32 — Write all high Voltage page latches with the same 32-bit data in a single write cycle Read always returns 0.
  {0x800+4j} FM_PL_DATA[{j}] (j=0..255) — Flash macro Page Latches data
    [31:0] DATA32 — Four page latch Bytes When reading the page latches it requires FM_CTL.IF_SEL to be '1' Note: the high Voltage page latches are readable for test mode functionality.
  {0xC00+4j} FM_MEM_DATA[{j}] (j=0..255) ro — Flash macro memory sense amplifier and column decoder data
    [31:0] DATA32 — Sense amplifier and cloumn multiplexer structure Bytes. The read data is dependent on FM_CTL.IF_SEL: - IF_SEL is '0': data as specified by the R interface address - IF_SEL is '1': data as specified by FM_MEM_ADDR and the offset of the accessed FM_MEM_DATA register.

## Notices in the file
Copyright 2016-2018, Cypress Semiconductor Corporation.  All rights reserved.
You may use this file only in accordance with the license, terms, conditions,
disclaimers, and limitations in the end user license agreement accompanying
the software package with which this file was provided.
